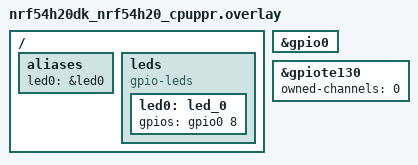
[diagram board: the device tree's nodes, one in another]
/*
 * Copyright (c) 2019 Nordic Semiconductor ASA
 *
 * SPDX-License-Identifier: Apache-2.0
 */

/ {
	aliases {
		led0 = &led0;
    };

    leds {
	compatible = "gpio-leds";

	led0: led_0 {
		gpios = <&gpio0 8 GPIO_ACTIVE_HIGH>;
          };
    };
};

&gpio0 {
    status = "okay";
};

&gpiote130 {
    status = "okay";
    owned-channels = < 0 >;
};
